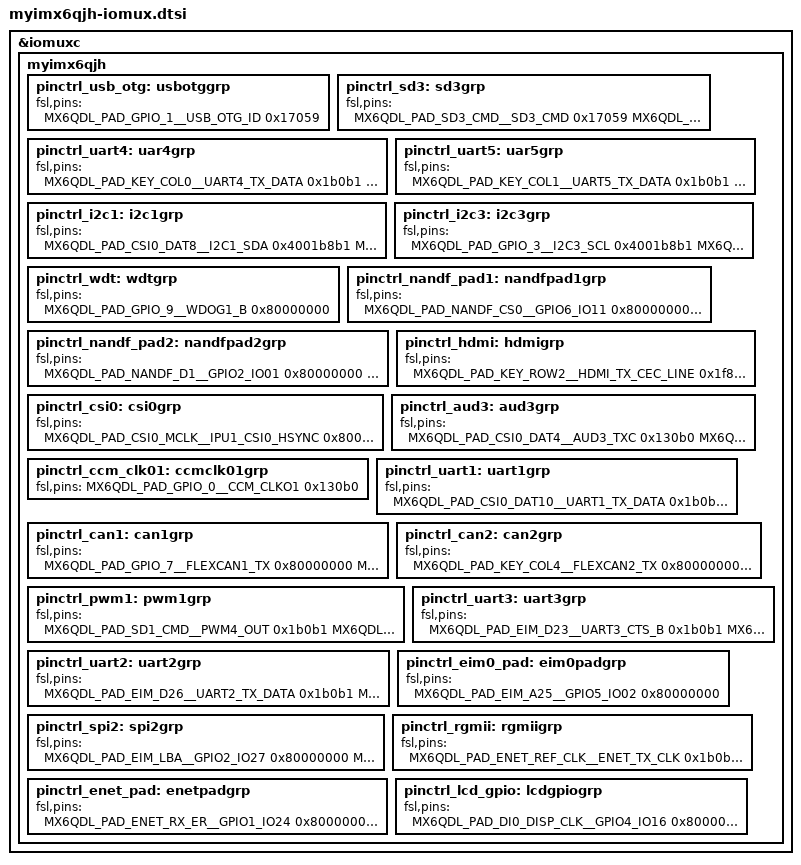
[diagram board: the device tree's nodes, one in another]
/*
 * MYZR Technology Co.,Ltd
 * http://www.myzr.com.cn
 * Tang Bin <tangb@myzr.com.cn>
 */

&iomuxc {
	myimx6qjh {
		pinctrl_usb_otg: usbotggrp {				/* J1 */
			fsl,pins = <
				MX6QDL_PAD_GPIO_1__USB_OTG_ID		0x17059
			>;
		};
		
		pinctrl_sd3: sd3grp {						/* U13 */
			fsl,pins = <
				MX6QDL_PAD_SD3_CMD__SD3_CMD			0x17059
				MX6QDL_PAD_SD3_CLK__SD3_CLK			0x10059
				MX6QDL_PAD_SD3_DAT0__SD3_DATA0		0x17059
				MX6QDL_PAD_SD3_DAT1__SD3_DATA1		0x17059
				MX6QDL_PAD_SD3_DAT2__SD3_DATA2		0x17059
				MX6QDL_PAD_SD3_DAT3__SD3_DATA3		0x17059
				/* CD */
				MX6QDL_PAD_SD3_DAT4__GPIO7_IO01		0x80000000
				/* RST */
				MX6QDL_PAD_SD3_RST__GPIO7_IO08		0x80000000
				/* MX6QDL_PAD_SD3_DAT6__GPIO6_IO18 Not use */
			>;
		};
		pinctrl_uart4: uar4grp {					/* J2 */
			fsl,pins = <
				MX6QDL_PAD_KEY_COL0__UART4_TX_DATA	0x1b0b1
				MX6QDL_PAD_KEY_ROW0__UART4_RX_DATA	0x1b0b1
			>;
		};
		pinctrl_uart5: uar5grp {					/* U8B */
			fsl,pins = <
				MX6QDL_PAD_KEY_COL1__UART5_TX_DATA	0x1b0b1
				MX6QDL_PAD_KEY_ROW1__UART5_RX_DATA	0x1b0b1
			>;
		};
		pinctrl_i2c1: i2c1grp {
			fsl,pins = <
				MX6QDL_PAD_CSI0_DAT8__I2C1_SDA		0x4001b8b1
				MX6QDL_PAD_CSI0_DAT9__I2C1_SCL		0x4001b8b1
			>;
		};
		pinctrl_i2c3: i2c3grp {						/* J2 */
			fsl,pins = <
				MX6QDL_PAD_GPIO_3__I2C3_SCL			0x4001b8b1
				MX6QDL_PAD_GPIO_6__I2C3_SDA			0x4001b8b1
			>;
		};
		
		pinctrl_wdt: wdtgrp {						/* ADM832 */
			fsl,pins = <
				MX6QDL_PAD_GPIO_9__WDOG1_B			0x80000000
			>;
		};
		
		pinctrl_nandf_pad1: nandfpad1grp {			/* J2 */
			fsl,pins = <
				MX6QDL_PAD_NANDF_CS0__GPIO6_IO11	0x80000000
				MX6QDL_PAD_NANDF_CS1__GPIO6_IO14	0x80000000
				MX6QDL_PAD_NANDF_CS2__GPIO6_IO15 	0x80000000
				MX6QDL_PAD_NANDF_CS3__GPIO6_IO16	0x80000000
				MX6QDL_PAD_NANDF_ALE__GPIO6_IO08	0x80000000
				MX6QDL_PAD_NANDF_CLE__GPIO6_IO07	0x80000000
				MX6QDL_PAD_NANDF_WP_B__GPIO6_IO09	0x80000000
				MX6QDL_PAD_NANDF_RB0__GPIO6_IO10 	0x80000000
				MX6QDL_PAD_NANDF_D0__GPIO2_IO00		0x80000000
				MX6QDL_PAD_NANDF_D3__GPIO2_IO03		0x80000000
				/* MX6QDL_PAD_NANDF_D4__GPIO2_IO04 Not use */
				MX6QDL_PAD_NANDF_D6__GPIO2_IO06		0x80000000
			>;
		};
		pinctrl_nandf_pad2: nandfpad2grp {			/* U8G */
			fsl,pins = <
				MX6QDL_PAD_NANDF_D1__GPIO2_IO01		0x80000000
				MX6QDL_PAD_NANDF_D2__GPIO2_IO02		0x80000000
				MX6QDL_PAD_NANDF_D5__GPIO2_IO05		0x80000000
				MX6QDL_PAD_NANDF_D7__GPIO2_IO07		0x80000000
			>;
		};
		
		pinctrl_hdmi: hdmigrp {								/* J2 */
			fsl,pins = <
				MX6QDL_PAD_KEY_ROW2__HDMI_TX_CEC_LINE		0x1f8b0
			>;
		};
		
		pinctrl_csi0: csi0grp {								/* U8C, U8H */
			fsl,pins = <
				/* U8C */
				MX6QDL_PAD_CSI0_MCLK__IPU1_CSI0_HSYNC		0x80000000
				MX6QDL_PAD_CSI0_DAT13__IPU1_CSI0_DATA13		0x80000000
				MX6QDL_PAD_CSI0_DAT14__IPU1_CSI0_DATA14		0x80000000
				MX6QDL_PAD_CSI0_DAT15__IPU1_CSI0_DATA15		0x80000000
				MX6QDL_PAD_CSI0_DAT16__IPU1_CSI0_DATA16		0x80000000
				MX6QDL_PAD_CSI0_DAT17__IPU1_CSI0_DATA17		0x80000000
				MX6QDL_PAD_CSI0_DAT18__IPU1_CSI0_DATA18		0x80000000
				MX6QDL_PAD_CSI0_DAT19__IPU1_CSI0_DATA19		0x80000000
				/* U8H */
				MX6QDL_PAD_CSI0_PIXCLK__IPU1_CSI0_PIXCLK	0x80000000
				MX6QDL_PAD_CSI0_VSYNC__IPU1_CSI0_VSYNC		0x80000000
				MX6QDL_PAD_CSI0_DAT12__IPU1_CSI0_DATA12		0x80000000
				MX6QDL_PAD_CSI0_DATA_EN__GPIO5_IO20			0x80000000
			>;
		};
		pinctrl_aud3: aud3grp {							/* J2 */
			fsl,pins = <
				MX6QDL_PAD_CSI0_DAT4__AUD3_TXC			0x130b0
				MX6QDL_PAD_CSI0_DAT5__AUD3_TXD			0x110b0
				MX6QDL_PAD_CSI0_DAT6__AUD3_TXFS			0x130b0
				MX6QDL_PAD_CSI0_DAT7__AUD3_RXD			0x130b0
			>;
		};
		pinctrl_ccm_clk01: ccmclk01grp {				/* J2 */
			fsl,pins = <
				MX6QDL_PAD_GPIO_0__CCM_CLKO1			0x130b0
			>;
		};
		
		pinctrl_uart1: uart1grp {						/* J4 */
			fsl,pins = <
				MX6QDL_PAD_CSI0_DAT10__UART1_TX_DATA	0x1b0b1
				MX6QDL_PAD_CSI0_DAT11__UART1_RX_DATA	0x1b0b1
			>;
		};
		pinctrl_can1: can1grp {							/* J2 */
			fsl,pins = <
				MX6QDL_PAD_GPIO_7__FLEXCAN1_TX			0x80000000
				MX6QDL_PAD_GPIO_8__FLEXCAN1_RX			0x80000000
			>;
		};
		pinctrl_can2: can2grp {							/* J2 */
			fsl,pins = <
				MX6QDL_PAD_KEY_COL4__FLEXCAN2_TX		0x80000000
				MX6QDL_PAD_KEY_ROW4__FLEXCAN2_RX		0x80000000
			>;
		};
		
		pinctrl_pwm1: pwm1grp {							/* J2 */
			fsl,pins = <
				MX6QDL_PAD_SD1_CMD__PWM4_OUT			0x1b0b1
				MX6QDL_PAD_SD1_DAT1__PWM3_OUT			0x1b0b1
				MX6QDL_PAD_SD1_DAT2__PWM2_OUT			0x1b0b1
				MX6QDL_PAD_SD1_DAT3__PWM1_OUT			0x1b0b1
			>;
		};
		
		pinctrl_uart3: uart3grp {						/* J2 */
			fsl,pins = <
				MX6QDL_PAD_EIM_D23__UART3_CTS_B			0x1b0b1
				MX6QDL_PAD_EIM_D24__UART3_TX_DATA		0x1b0b1
				MX6QDL_PAD_EIM_D25__UART3_RX_DATA		0x1b0b1
				MX6QDL_PAD_EIM_D31__UART3_RTS_B			0x1b0b1
			>;
		};
		pinctrl_uart2: uart2grp {						/* J2 */
			fsl,pins = <
				MX6QDL_PAD_EIM_D26__UART2_TX_DATA		0x1b0b1
				MX6QDL_PAD_EIM_D27__UART2_RX_DATA		0x1b0b1
				MX6QDL_PAD_EIM_D28__UART2_CTS_B			0x1b0b1
				MX6QDL_PAD_EIM_D29__UART2_RTS_B			0x1b0b1
			>;
		};
		
		pinctrl_eim0_pad: eim0padgrp {					/* J2 */
			fsl,pins = <
				MX6QDL_PAD_EIM_A25__GPIO5_IO02			0x80000000
			>;
		};
		pinctrl_spi2: spi2grp {							/* J2 */
			fsl,pins = <
				/* SPI2_CS1 */
				MX6QDL_PAD_EIM_LBA__GPIO2_IO27			0x80000000
				MX6QDL_PAD_EIM_OE__ECSPI2_MISO 			0x100b1
				/* SPI2_CS0 */
				MX6QDL_PAD_EIM_RW__GPIO2_IO26			0x80000000
				MX6QDL_PAD_EIM_CS0__ECSPI2_SCLK 		0x100b1
				MX6QDL_PAD_EIM_CS1__ECSPI2_MOSI 		0x100b1
			>;
		};
		
		pinctrl_rgmii: rgmiigrp {						/* U5 */
			fsl,pins = <
				MX6QDL_PAD_ENET_REF_CLK__ENET_TX_CLK	0x1b0b0
				MX6QDL_PAD_ENET_MDIO__ENET_MDIO			0x1b0b0
				/* Reset */
				MX6QDL_PAD_ENET_CRS_DV__GPIO1_IO25		0x80000000
				/* INT */
				MX6QDL_PAD_ENET_TX_EN__GPIO1_IO28		0x000b1
				MX6QDL_PAD_ENET_MDC__ENET_MDC			0x1b0b0
				MX6QDL_PAD_RGMII_TXC__RGMII_TXC			0x1b0b0
				MX6QDL_PAD_RGMII_TD0__RGMII_TD0			0x1b0b0
				MX6QDL_PAD_RGMII_TD1__RGMII_TD1			0x1b0b0
				MX6QDL_PAD_RGMII_TD2__RGMII_TD2			0x1b0b0
				MX6QDL_PAD_RGMII_TD3__RGMII_TD3			0x1b0b0
				MX6QDL_PAD_RGMII_TX_CTL__RGMII_TX_CTL	0x1b0b0
				MX6QDL_PAD_RGMII_RXC__RGMII_RXC			0x1b0b0
				MX6QDL_PAD_RGMII_RD0__RGMII_RD0			0x1b0b0
				MX6QDL_PAD_RGMII_RD1__RGMII_RD1			0x1b0b0
				MX6QDL_PAD_RGMII_RD2__RGMII_RD2			0x1b0b0
				MX6QDL_PAD_RGMII_RD3__RGMII_RD3			0x1b0b0
				MX6QDL_PAD_RGMII_RX_CTL__RGMII_RX_CTL	0x1b0b0
			>;
		};
		
		pinctrl_enet_pad: enetpadgrp {
			fsl,pins = <
				/* J2 */
				MX6QDL_PAD_ENET_RX_ER__GPIO1_IO24		0x80000000
				/* U8F */
				MX6QDL_PAD_EIM_D20__GPIO3_IO20			0x80000000
				/* J2 */
				MX6QDL_PAD_ENET_TXD1__GPIO1_IO29		0x80000000
				/* J2 */
				MX6QDL_PAD_ENET_RXD0__GPIO1_IO27		0x80000000
				/* U8B */
				MX6QDL_PAD_ENET_RXD1__GPIO1_IO26		0x80000000
			>;
		};
		
		pinctrl_lcd_gpio: lcdgpiogrp {					/* J2 */
			fsl,pins = <
				MX6QDL_PAD_DI0_DISP_CLK__GPIO4_IO16		0x80000000
				MX6QDL_PAD_DI0_PIN2__GPIO4_IO18			0x80000000
				MX6QDL_PAD_DI0_PIN3__GPIO4_IO19			0x80000000
				MX6QDL_PAD_DI0_PIN4__GPIO4_IO20			0x80000000
				MX6QDL_PAD_DI0_PIN15__GPIO4_IO17		0x80000000
				MX6QDL_PAD_DISP0_DAT0__GPIO4_IO21		0x80000000
				MX6QDL_PAD_DISP0_DAT1__GPIO4_IO22		0x80000000
				MX6QDL_PAD_DISP0_DAT2__GPIO4_IO23		0x80000000
				MX6QDL_PAD_DISP0_DAT3__GPIO4_IO24		0x80000000
				MX6QDL_PAD_DISP0_DAT4__GPIO4_IO25		0x80000000
				MX6QDL_PAD_DISP0_DAT5__GPIO4_IO26		0x80000000
				MX6QDL_PAD_DISP0_DAT6__GPIO4_IO27		0x80000000
				MX6QDL_PAD_DISP0_DAT7__GPIO4_IO28		0x80000000
				MX6QDL_PAD_DISP0_DAT8__GPIO4_IO29		0x80000000
				MX6QDL_PAD_DISP0_DAT9__GPIO4_IO30		0x80000000
				MX6QDL_PAD_DISP0_DAT10__GPIO4_IO31		0x80000000
				MX6QDL_PAD_DISP0_DAT11__GPIO5_IO05		0x80000000
				MX6QDL_PAD_DISP0_DAT12__GPIO5_IO06		0x80000000
				MX6QDL_PAD_DISP0_DAT13__GPIO5_IO07		0x80000000
				MX6QDL_PAD_DISP0_DAT14__GPIO5_IO08		0x80000000
				MX6QDL_PAD_DISP0_DAT15__GPIO5_IO09		0x80000000
				MX6QDL_PAD_DISP0_DAT16__GPIO5_IO10		0x80000000
				MX6QDL_PAD_DISP0_DAT17__GPIO5_IO11		0x80000000
				MX6QDL_PAD_DISP0_DAT18__GPIO5_IO12		0x80000000
				MX6QDL_PAD_DISP0_DAT19__GPIO5_IO13		0x80000000
				MX6QDL_PAD_DISP0_DAT20__GPIO5_IO14		0x80000000
				MX6QDL_PAD_DISP0_DAT21__GPIO5_IO15		0x80000000
				MX6QDL_PAD_DISP0_DAT22__GPIO5_IO16		0x80000000
				MX6QDL_PAD_DISP0_DAT23__GPIO5_IO17		0x80000000
			>;
		};
	};
};
